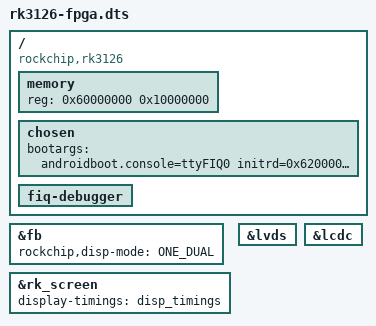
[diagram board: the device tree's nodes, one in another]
// SPDX-License-Identifier: (GPL-2.0+ OR MIT)
/dts-v1/;
#include "rk312x.dtsi"
#include "rk312x-pinctrl.dtsi"
#include "lcd-td043mgeal.dtsi"

/ {
	compatible = "rockchip,rk3126";

	memory {
		device_type = "memory";
		reg = <0x60000000 0x10000000>;
	};

	chosen {
		bootargs = "androidboot.console=ttyFIQ0 initrd=0x62000000,0x00800000";
	};

	fiq-debugger {
		status = "okay";
	};

};

&fb {
	rockchip,disp-mode = <ONE_DUAL>;
};

&rk_screen {
	display-timings = <&disp_timings>;
};

&lvds {
	status = "okay";
};

&lcdc {
	status = "okay";
};
